VERSION ""

NS_ :

BS_:

BU_: HOST ECU

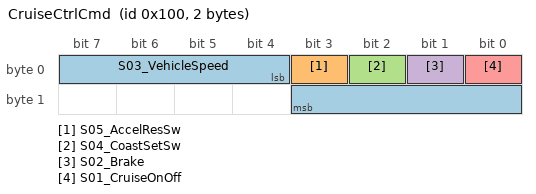
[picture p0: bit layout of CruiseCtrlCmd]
BO_ 256 CruiseCtrlCmd: 2 HOST
 SG_ S03_VehicleSpeed : 4|8@1+ (1,0) [0|255] ""  ECU
 SG_ S05_AccelResSw : 3|1@1+ (1,0) [0|1] ""  ECU
 SG_ S04_CoastSetSw : 2|1@1+ (1,0) [0|1] ""  ECU
 SG_ S02_Brake : 1|1@1+ (1,0) [0|1] ""  ECU
 SG_ S01_CruiseOnOff : 0|1@1+ (1,0) [0|1] ""  ECU

BO_ 512 CruiseCtrlFB: 2 ECU
 SG_ F02_TargetSpeed : 1|8@1+ (1,0) [0|255] ""  HOST
 SG_ F01_Engaged : 0|1@1+ (1,0) [0|1] ""  HOST

BA_DEF_  "BusType" STRING ;
BA_DEF_DEF_  "BusType" "CAN";
